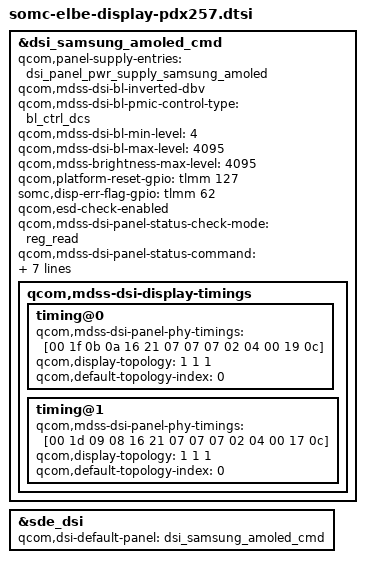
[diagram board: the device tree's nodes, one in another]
#include "dsi-panel-pdx257.dtsi"

&dsi_samsung_amoled_cmd {
	qcom,panel-supply-entries = <&dsi_panel_pwr_supply_samsung_amoled>;
	qcom,mdss-dsi-bl-inverted-dbv;
	qcom,mdss-dsi-bl-pmic-control-type = "bl_ctrl_dcs";
	qcom,mdss-dsi-bl-min-level = <4>;
	qcom,mdss-dsi-bl-max-level = <4095>;
	qcom,mdss-brightness-max-level = <4095>;
	qcom,platform-reset-gpio = <&tlmm 127 0>;
	somc,disp-err-flag-gpio = <&tlmm 62 0>;

	qcom,esd-check-enabled;
	qcom,mdss-dsi-panel-status-check-mode = "reg_read";
	qcom,mdss-dsi-panel-status-command = [06 01 00 01 00 00 01 0a];
	qcom,mdss-dsi-panel-status-command-state = "dsi_lp_mode";
	qcom,mdss-dsi-panel-status-value = <0x9C>;
	qcom,mdss-dsi-panel-status-read-length = <1>;
	qcom,dsi-select-clocks = "pll_byte_clk0", "pll_dsi_clk0";

	qcom,mdss-dsi-display-timings {
		timing@0 {
			qcom,mdss-dsi-panel-phy-timings = [00 1f 0b 0a 16 21 07
				07 07 02 04 00 19 0c];
			qcom,display-topology = <1 1 1>;
			qcom,default-topology-index = <0>;
		};

		timing@1 {
			qcom,mdss-dsi-panel-phy-timings = [00 1d 09 08 16 21 07
				07 07 02 04 00 17 0c];
			qcom,display-topology = <1 1 1>;
			qcom,default-topology-index = <0>;
		};
	};
};

&sde_dsi {
	qcom,dsi-default-panel = <&dsi_samsung_amoled_cmd>;
};
